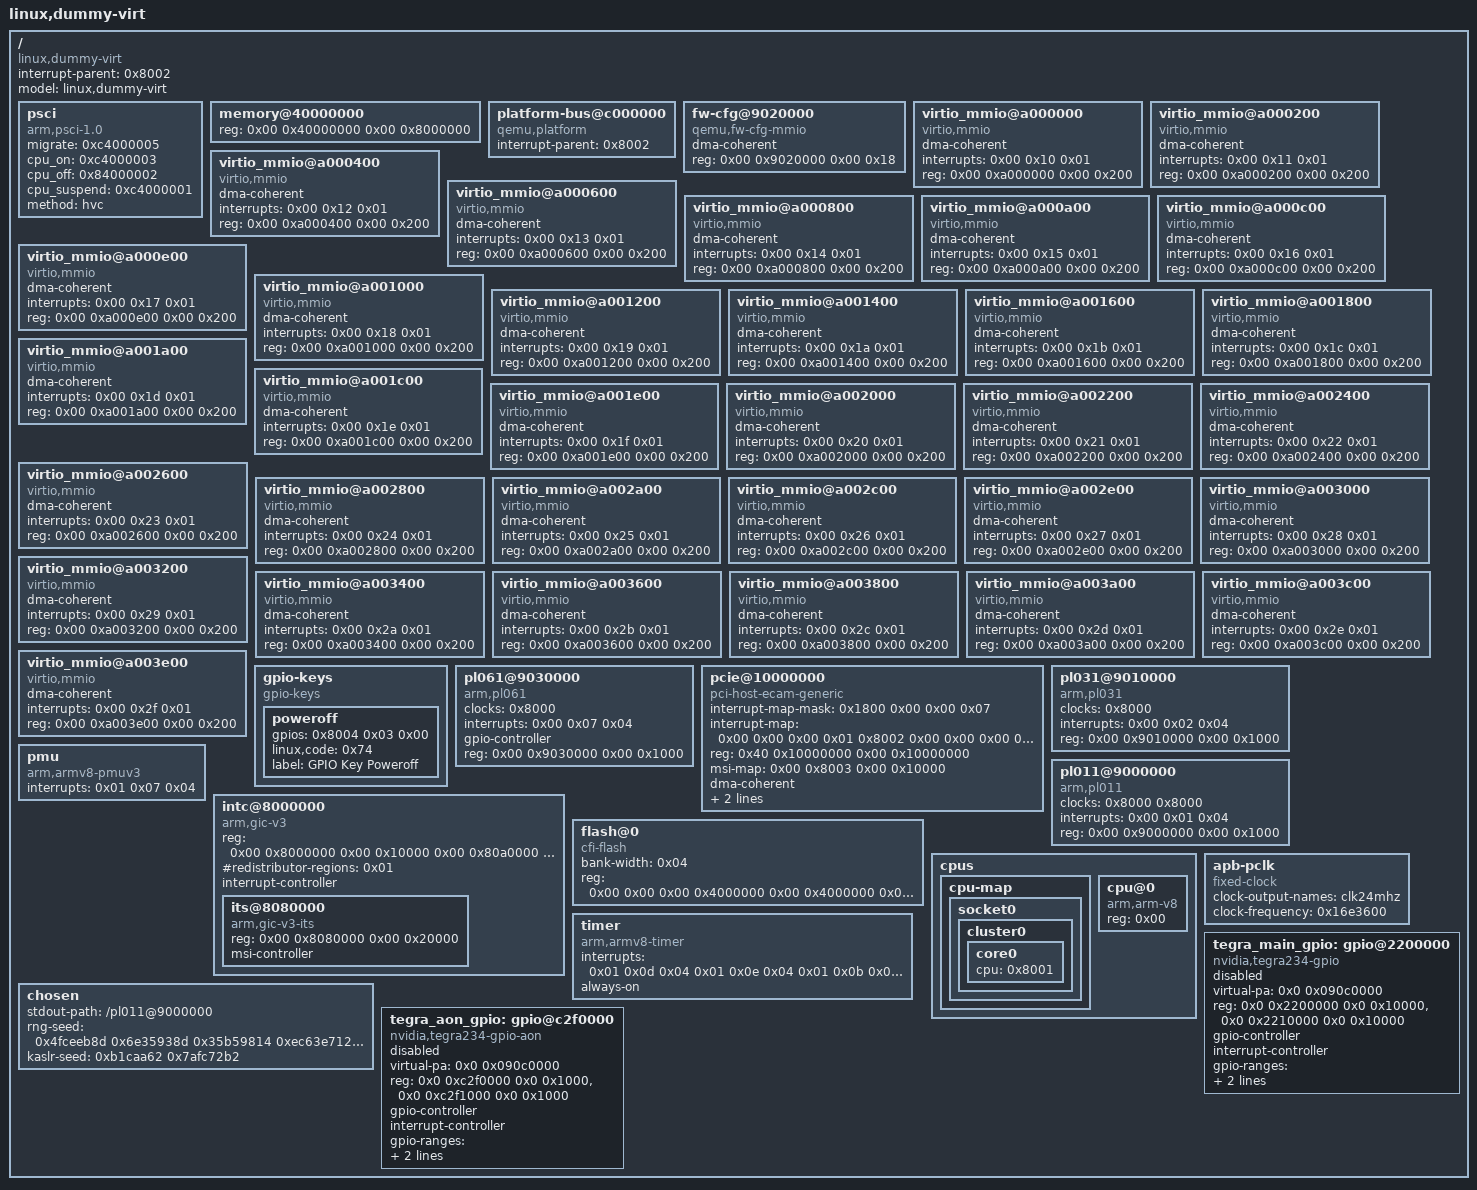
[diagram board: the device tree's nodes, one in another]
/dts-v1/;

/ {
	interrupt-parent = <0x8002>;
	model = "linux,dummy-virt";
	#size-cells = <0x02>;
	#address-cells = <0x02>;
	compatible = "linux,dummy-virt";

	psci {
		migrate = <0xc4000005>;
		cpu_on = <0xc4000003>;
		cpu_off = <0x84000002>;
		cpu_suspend = <0xc4000001>;
		method = "hvc";
		compatible = "arm,psci-1.0\0arm,psci-0.2\0arm,psci";
	};

	memory@40000000 {
		reg = <0x00 0x40000000 0x00 0x8000000>;
		device_type = "memory";
	};

	platform-bus@c000000 {
		interrupt-parent = <0x8002>;
		ranges = <0xc000000 0x00 0xc000000 0x2000000>;
		#address-cells = <0x01>;
		#size-cells = <0x01>;
		compatible = "qemu,platform\0simple-bus";

		// we ned to declare gpio here?
		// gpio { };
	};

	fw-cfg@9020000 {
		dma-coherent;
		reg = <0x00 0x9020000 0x00 0x18>;
		compatible = "qemu,fw-cfg-mmio";
	};

	virtio_mmio@a000000 {
		dma-coherent;
		interrupts = <0x00 0x10 0x01>;
		reg = <0x00 0xa000000 0x00 0x200>;
		compatible = "virtio,mmio";
	};

	virtio_mmio@a000200 {
		dma-coherent;
		interrupts = <0x00 0x11 0x01>;
		reg = <0x00 0xa000200 0x00 0x200>;
		compatible = "virtio,mmio";
	};

	virtio_mmio@a000400 {
		dma-coherent;
		interrupts = <0x00 0x12 0x01>;
		reg = <0x00 0xa000400 0x00 0x200>;
		compatible = "virtio,mmio";
	};

	virtio_mmio@a000600 {
		dma-coherent;
		interrupts = <0x00 0x13 0x01>;
		reg = <0x00 0xa000600 0x00 0x200>;
		compatible = "virtio,mmio";
	};

	virtio_mmio@a000800 {
		dma-coherent;
		interrupts = <0x00 0x14 0x01>;
		reg = <0x00 0xa000800 0x00 0x200>;
		compatible = "virtio,mmio";
	};

	virtio_mmio@a000a00 {
		dma-coherent;
		interrupts = <0x00 0x15 0x01>;
		reg = <0x00 0xa000a00 0x00 0x200>;
		compatible = "virtio,mmio";
	};

	virtio_mmio@a000c00 {
		dma-coherent;
		interrupts = <0x00 0x16 0x01>;
		reg = <0x00 0xa000c00 0x00 0x200>;
		compatible = "virtio,mmio";
	};

	virtio_mmio@a000e00 {
		dma-coherent;
		interrupts = <0x00 0x17 0x01>;
		reg = <0x00 0xa000e00 0x00 0x200>;
		compatible = "virtio,mmio";
	};

	virtio_mmio@a001000 {
		dma-coherent;
		interrupts = <0x00 0x18 0x01>;
		reg = <0x00 0xa001000 0x00 0x200>;
		compatible = "virtio,mmio";
	};

	virtio_mmio@a001200 {
		dma-coherent;
		interrupts = <0x00 0x19 0x01>;
		reg = <0x00 0xa001200 0x00 0x200>;
		compatible = "virtio,mmio";
	};

	virtio_mmio@a001400 {
		dma-coherent;
		interrupts = <0x00 0x1a 0x01>;
		reg = <0x00 0xa001400 0x00 0x200>;
		compatible = "virtio,mmio";
	};

	virtio_mmio@a001600 {
		dma-coherent;
		interrupts = <0x00 0x1b 0x01>;
		reg = <0x00 0xa001600 0x00 0x200>;
		compatible = "virtio,mmio";
	};

	virtio_mmio@a001800 {
		dma-coherent;
		interrupts = <0x00 0x1c 0x01>;
		reg = <0x00 0xa001800 0x00 0x200>;
		compatible = "virtio,mmio";
	};

	virtio_mmio@a001a00 {
		dma-coherent;
		interrupts = <0x00 0x1d 0x01>;
		reg = <0x00 0xa001a00 0x00 0x200>;
		compatible = "virtio,mmio";
	};

	virtio_mmio@a001c00 {
		dma-coherent;
		interrupts = <0x00 0x1e 0x01>;
		reg = <0x00 0xa001c00 0x00 0x200>;
		compatible = "virtio,mmio";
	};

	virtio_mmio@a001e00 {
		dma-coherent;
		interrupts = <0x00 0x1f 0x01>;
		reg = <0x00 0xa001e00 0x00 0x200>;
		compatible = "virtio,mmio";
	};

	virtio_mmio@a002000 {
		dma-coherent;
		interrupts = <0x00 0x20 0x01>;
		reg = <0x00 0xa002000 0x00 0x200>;
		compatible = "virtio,mmio";
	};

	virtio_mmio@a002200 {
		dma-coherent;
		interrupts = <0x00 0x21 0x01>;
		reg = <0x00 0xa002200 0x00 0x200>;
		compatible = "virtio,mmio";
	};

	virtio_mmio@a002400 {
		dma-coherent;
		interrupts = <0x00 0x22 0x01>;
		reg = <0x00 0xa002400 0x00 0x200>;
		compatible = "virtio,mmio";
	};

	virtio_mmio@a002600 {
		dma-coherent;
		interrupts = <0x00 0x23 0x01>;
		reg = <0x00 0xa002600 0x00 0x200>;
		compatible = "virtio,mmio";
	};

	virtio_mmio@a002800 {
		dma-coherent;
		interrupts = <0x00 0x24 0x01>;
		reg = <0x00 0xa002800 0x00 0x200>;
		compatible = "virtio,mmio";
	};

	virtio_mmio@a002a00 {
		dma-coherent;
		interrupts = <0x00 0x25 0x01>;
		reg = <0x00 0xa002a00 0x00 0x200>;
		compatible = "virtio,mmio";
	};

	virtio_mmio@a002c00 {
		dma-coherent;
		interrupts = <0x00 0x26 0x01>;
		reg = <0x00 0xa002c00 0x00 0x200>;
		compatible = "virtio,mmio";
	};

	virtio_mmio@a002e00 {
		dma-coherent;
		interrupts = <0x00 0x27 0x01>;
		reg = <0x00 0xa002e00 0x00 0x200>;
		compatible = "virtio,mmio";
	};

	virtio_mmio@a003000 {
		dma-coherent;
		interrupts = <0x00 0x28 0x01>;
		reg = <0x00 0xa003000 0x00 0x200>;
		compatible = "virtio,mmio";
	};

	virtio_mmio@a003200 {
		dma-coherent;
		interrupts = <0x00 0x29 0x01>;
		reg = <0x00 0xa003200 0x00 0x200>;
		compatible = "virtio,mmio";
	};

	virtio_mmio@a003400 {
		dma-coherent;
		interrupts = <0x00 0x2a 0x01>;
		reg = <0x00 0xa003400 0x00 0x200>;
		compatible = "virtio,mmio";
	};

	virtio_mmio@a003600 {
		dma-coherent;
		interrupts = <0x00 0x2b 0x01>;
		reg = <0x00 0xa003600 0x00 0x200>;
		compatible = "virtio,mmio";
	};

	virtio_mmio@a003800 {
		dma-coherent;
		interrupts = <0x00 0x2c 0x01>;
		reg = <0x00 0xa003800 0x00 0x200>;
		compatible = "virtio,mmio";
	};

	virtio_mmio@a003a00 {
		dma-coherent;
		interrupts = <0x00 0x2d 0x01>;
		reg = <0x00 0xa003a00 0x00 0x200>;
		compatible = "virtio,mmio";
	};

	virtio_mmio@a003c00 {
		dma-coherent;
		interrupts = <0x00 0x2e 0x01>;
		reg = <0x00 0xa003c00 0x00 0x200>;
		compatible = "virtio,mmio";
	};

	virtio_mmio@a003e00 {
		dma-coherent;
		interrupts = <0x00 0x2f 0x01>;
		reg = <0x00 0xa003e00 0x00 0x200>;
		compatible = "virtio,mmio";
	};

	gpio-keys {
		compatible = "gpio-keys";

		poweroff {
			gpios = <0x8004 0x03 0x00>;
			linux,code = <0x74>;
			label = "GPIO Key Poweroff";
		};
	};

	pl061@9030000 {
		phandle = <0x8004>;
		clock-names = "apb_pclk";
		clocks = <0x8000>;
		interrupts = <0x00 0x07 0x04>;
		gpio-controller;
		#gpio-cells = <0x02>;
		compatible = "arm,pl061\0arm,primecell";
		reg = <0x00 0x9030000 0x00 0x1000>;
	};

	pcie@10000000 {
		interrupt-map-mask = <0x1800 0x00 0x00 0x07>;
		interrupt-map = <0x00 0x00 0x00 0x01 0x8002 0x00 0x00 0x00 0x03 0x04 0x00 0x00 0x00 0x02 0x8002 0x00 0x00 0x00 0x04 0x04 0x00 0x00 0x00 0x03 0x8002 0x00 0x00 0x00 0x05 0x04 0x00 0x00 0x00 0x04 0x8002 0x00 0x00 0x00 0x06 0x04 0x800 0x00 0x00 0x01 0x8002 0x00 0x00 0x00 0x04 0x04 0x800 0x00 0x00 0x02 0x8002 0x00 0x00 0x00 0x05 0x04 0x800 0x00 0x00 0x03 0x8002 0x00 0x00 0x00 0x06 0x04 0x800 0x00 0x00 0x04 0x8002 0x00 0x00 0x00 0x03 0x04 0x1000 0x00 0x00 0x01 0x8002 0x00 0x00 0x00 0x05 0x04 0x1000 0x00 0x00 0x02 0x8002 0x00 0x00 0x00 0x06 0x04 0x1000 0x00 0x00 0x03 0x8002 0x00 0x00 0x00 0x03 0x04 0x1000 0x00 0x00 0x04 0x8002 0x00 0x00 0x00 0x04 0x04 0x1800 0x00 0x00 0x01 0x8002 0x00 0x00 0x00 0x06 0x04 0x1800 0x00 0x00 0x02 0x8002 0x00 0x00 0x00 0x03 0x04 0x1800 0x00 0x00 0x03 0x8002 0x00 0x00 0x00 0x04 0x04 0x1800 0x00 0x00 0x04 0x8002 0x00 0x00 0x00 0x05 0x04>;
		#interrupt-cells = <0x01>;
		ranges = <0x1000000 0x00 0x00 0x00 0x3eff0000 0x00 0x10000 0x2000000 0x00 0x10000000 0x00 0x10000000 0x00 0x2eff0000 0x3000000 0x80 0x00 0x80 0x00 0x80 0x00>;
		reg = <0x40 0x10000000 0x00 0x10000000>;
		msi-map = <0x00 0x8003 0x00 0x10000>;
		dma-coherent;
		bus-range = <0x00 0xff>;
		linux,pci-domain = <0x00>;
		#size-cells = <0x02>;
		#address-cells = <0x03>;
		device_type = "pci";
		compatible = "pci-host-ecam-generic";
	};

	pl031@9010000 {
		clock-names = "apb_pclk";
		clocks = <0x8000>;
		interrupts = <0x00 0x02 0x04>;
		reg = <0x00 0x9010000 0x00 0x1000>;
		compatible = "arm,pl031\0arm,primecell";
	};

	pl011@9000000 {
		clock-names = "uartclk\0apb_pclk";
		clocks = <0x8000 0x8000>;
		interrupts = <0x00 0x01 0x04>;
		reg = <0x00 0x9000000 0x00 0x1000>;
		compatible = "arm,pl011\0arm,primecell";
	};

	pmu {
		interrupts = <0x01 0x07 0x04>;
		compatible = "arm,armv8-pmuv3";
	};

	intc@8000000 {
		phandle = <0x8002>;
		reg = <0x00 0x8000000 0x00 0x10000 0x00 0x80a0000 0x00 0xf60000>;
		#redistributor-regions = <0x01>;
		compatible = "arm,gic-v3";
		ranges;
		#size-cells = <0x02>;
		#address-cells = <0x02>;
		interrupt-controller;
		#interrupt-cells = <0x03>;

		its@8080000 {
			phandle = <0x8003>;
			reg = <0x00 0x8080000 0x00 0x20000>;
			#msi-cells = <0x01>;
			msi-controller;
			compatible = "arm,gic-v3-its";
		};
	};

	flash@0 {
		bank-width = <0x04>;
		reg = <0x00 0x00 0x00 0x4000000 0x00 0x4000000 0x00 0x4000000>;
		compatible = "cfi-flash";
	};

	cpus {
		#size-cells = <0x00>;
		#address-cells = <0x01>;

		cpu-map {

			socket0 {

				cluster0 {

					core0 {
						cpu = <0x8001>;
					};
				};
			};
		};

		cpu@0 {
			phandle = <0x8001>;
			reg = <0x00>;
			compatible = "arm,arm-v8";
			device_type = "cpu";
		};
	};

	timer {
		interrupts = <0x01 0x0d 0x04 0x01 0x0e 0x04 0x01 0x0b 0x04 0x01 0x0a 0x04>;
		always-on;
		compatible = "arm,armv8-timer\0arm,armv7-timer";
	};

	apb-pclk {
		phandle = <0x8000>;
		clock-output-names = "clk24mhz";
		clock-frequency = <0x16e3600>;
		#clock-cells = <0x00>;
		compatible = "fixed-clock";
	};

	chosen {
		stdout-path = "/pl011@9000000";
		rng-seed = <0x4fceeb8d 0x6e35938d 0x35b59814 0xec63e712 0xbead8845 0x16c4983a 0xd49ee22f 0x9e88673f>;
		kaslr-seed = <0xb1caa62 0x7afc72b2>;
	};

	// gpiochip0, gpiochip348, GPIOs 348-511, label=tegra234-gpio
	tegra_main_gpio: gpio@2200000 {
		compatible = "nvidia,tegra234-gpio";
		// change this address to not overlap bpmp vpa or other gpio chip
		virtual-pa = <0x0 0x090c0000>; 
		reg-names = "security", "gpio";
		reg =
			<0x0 0x2200000 0x0 0x10000>,
			<0x0 0x2210000 0x0 0x10000>;
		/* we have no irq passthrough
		interrupts =
			<0 TEGRA234_IRQ_GPIO0_0 IRQ_TYPE_LEVEL_HIGH>,
			<0 TEGRA234_IRQ_GPIO0_1 IRQ_TYPE_LEVEL_HIGH>,
			<0 TEGRA234_IRQ_GPIO0_2 IRQ_TYPE_LEVEL_HIGH>,
			<0 TEGRA234_IRQ_GPIO0_3 IRQ_TYPE_LEVEL_HIGH>,
			<0 TEGRA234_IRQ_GPIO0_4 IRQ_TYPE_LEVEL_HIGH>,
			<0 TEGRA234_IRQ_GPIO0_5 IRQ_TYPE_LEVEL_HIGH>,
			<0 TEGRA234_IRQ_GPIO0_6 IRQ_TYPE_LEVEL_HIGH>,
			<0 TEGRA234_IRQ_GPIO0_7 IRQ_TYPE_LEVEL_HIGH>,
			<0 TEGRA234_IRQ_GPIO1_0 IRQ_TYPE_LEVEL_HIGH>,
			<0 TEGRA234_IRQ_GPIO1_1 IRQ_TYPE_LEVEL_HIGH>,
			<0 TEGRA234_IRQ_GPIO1_2 IRQ_TYPE_LEVEL_HIGH>,
			<0 TEGRA234_IRQ_GPIO1_3 IRQ_TYPE_LEVEL_HIGH>,
			<0 TEGRA234_IRQ_GPIO1_4 IRQ_TYPE_LEVEL_HIGH>,
			<0 TEGRA234_IRQ_GPIO1_5 IRQ_TYPE_LEVEL_HIGH>,
			<0 TEGRA234_IRQ_GPIO1_6 IRQ_TYPE_LEVEL_HIGH>,
			<0 TEGRA234_IRQ_GPIO1_7 IRQ_TYPE_LEVEL_HIGH>,
			<0 TEGRA234_IRQ_GPIO2_0 IRQ_TYPE_LEVEL_HIGH>,
			<0 TEGRA234_IRQ_GPIO2_1 IRQ_TYPE_LEVEL_HIGH>,
			<0 TEGRA234_IRQ_GPIO2_2 IRQ_TYPE_LEVEL_HIGH>,
			<0 TEGRA234_IRQ_GPIO2_3 IRQ_TYPE_LEVEL_HIGH>,
			<0 TEGRA234_IRQ_GPIO2_4 IRQ_TYPE_LEVEL_HIGH>,
			<0 TEGRA234_IRQ_GPIO2_5 IRQ_TYPE_LEVEL_HIGH>,
			<0 TEGRA234_IRQ_GPIO2_6 IRQ_TYPE_LEVEL_HIGH>,
			<0 TEGRA234_IRQ_GPIO2_7 IRQ_TYPE_LEVEL_HIGH>,
			<0 TEGRA234_IRQ_GPIO3_0 IRQ_TYPE_LEVEL_HIGH>,
			<0 TEGRA234_IRQ_GPIO3_1 IRQ_TYPE_LEVEL_HIGH>,
			<0 TEGRA234_IRQ_GPIO3_2 IRQ_TYPE_LEVEL_HIGH>,
			<0 TEGRA234_IRQ_GPIO3_3 IRQ_TYPE_LEVEL_HIGH>,
			<0 TEGRA234_IRQ_GPIO3_4 IRQ_TYPE_LEVEL_HIGH>,
			<0 TEGRA234_IRQ_GPIO3_5 IRQ_TYPE_LEVEL_HIGH>,
			<0 TEGRA234_IRQ_GPIO3_6 IRQ_TYPE_LEVEL_HIGH>,
			<0 TEGRA234_IRQ_GPIO3_7 IRQ_TYPE_LEVEL_HIGH>,
			<0 TEGRA234_IRQ_GPIO4_0 IRQ_TYPE_LEVEL_HIGH>,
			<0 TEGRA234_IRQ_GPIO4_1 IRQ_TYPE_LEVEL_HIGH>,
			<0 TEGRA234_IRQ_GPIO4_2 IRQ_TYPE_LEVEL_HIGH>,
			<0 TEGRA234_IRQ_GPIO4_3 IRQ_TYPE_LEVEL_HIGH>,
			<0 TEGRA234_IRQ_GPIO4_4 IRQ_TYPE_LEVEL_HIGH>,
			<0 TEGRA234_IRQ_GPIO4_5 IRQ_TYPE_LEVEL_HIGH>,
			<0 TEGRA234_IRQ_GPIO4_6 IRQ_TYPE_LEVEL_HIGH>,
			<0 TEGRA234_IRQ_GPIO4_7 IRQ_TYPE_LEVEL_HIGH>,
			<0 TEGRA234_IRQ_GPIO5_0 IRQ_TYPE_LEVEL_HIGH>,
			<0 TEGRA234_IRQ_GPIO5_1 IRQ_TYPE_LEVEL_HIGH>,
			<0 TEGRA234_IRQ_GPIO5_2 IRQ_TYPE_LEVEL_HIGH>,
			<0 TEGRA234_IRQ_GPIO5_3 IRQ_TYPE_LEVEL_HIGH>,
			<0 TEGRA234_IRQ_GPIO5_4 IRQ_TYPE_LEVEL_HIGH>,
			<0 TEGRA234_IRQ_GPIO5_5 IRQ_TYPE_LEVEL_HIGH>,
			<0 TEGRA234_IRQ_GPIO5_6 IRQ_TYPE_LEVEL_HIGH>,
			<0 TEGRA234_IRQ_GPIO5_7 IRQ_TYPE_LEVEL_HIGH>;
		*/
		gpio-controller;
		#gpio-cells = <2>;
		interrupt-controller;
		#interrupt-cells = <2>;
		gpio-ranges =
			<&tegra_pinctrl TEGRA234_MAIN_GPIO_OFFSET TEGRA234_MAIN_PINCTRL_OFFSET_A TEGRA234_MAIN_PINS_A_TO_Z>,
			<&tegra_pinctrl TEGRA234_MAIN_PINS_A_TO_Z TEGRA234_MAIN_PINCTRL_OFFSET_AC TEGRA234_MAIN_PINS_AC_TO_AG>;
		status = "disabled";
	};

	// gpiochip1, gpiochip316, GPIOs 316-347, label=tegra234-gpio-aon
	tegra_aon_gpio: gpio@c2f0000 {
		compatible = "nvidia,tegra234-gpio-aon";
		// change this address to not overlap bpmp vpa or other gpio chip
		virtual-pa = <0x0 0x090c0000>; 
		reg-names = "security", "gpio";
		reg = 	<0x0 0xc2f0000 0x0 0x1000>,
			<0x0 0xc2f1000 0x0 0x1000>;
		/* we have no irq passthrough
		interrupts =
			<0 TEGRA234_IRQ_AON_GPIO_0 IRQ_TYPE_LEVEL_HIGH>,
			<0 TEGRA234_IRQ_AON_GPIO_1 IRQ_TYPE_LEVEL_HIGH>,
			<0 TEGRA234_IRQ_AON_GPIO_2 IRQ_TYPE_LEVEL_HIGH>,
			<0 TEGRA234_IRQ_AON_GPIO_3 IRQ_TYPE_LEVEL_HIGH>;
		*/
		gpio-controller;
		#gpio-cells = <2>;
		interrupt-controller;
		#interrupt-cells = <2>;
		gpio-ranges =
			<&tegra_pinctrl TEGRA234_MAIN_GPIO_OFFSET TEGRA234_MAIN_PINS_A_TO_Z TEGRA234_AON_PINS_AA>,
			<&tegra_pinctrl TEGRA234_AON_PINS_AA TEGRA234_AON_PINCTRL_OFFSET_BB TEGRA234_AON_PINS_BB_TO_GG>;
		status = "disabled";
	};


};
